# APM32L08x register map
File version: 1.0
CPU: CM0+ r0p0, little endian, MPU, no FPU, 4 interrupt priority bits
Registers are 32-bit, read-write, reset 0x0 unless marked. A register's access mark holds for its fields unless they carry their own. Offsets are from the block's base; [hi:lo] are bit positions; {n}, {i} and the like mark numbered series.

## ADC — Analog-to-digital converter
Base 0x40012400
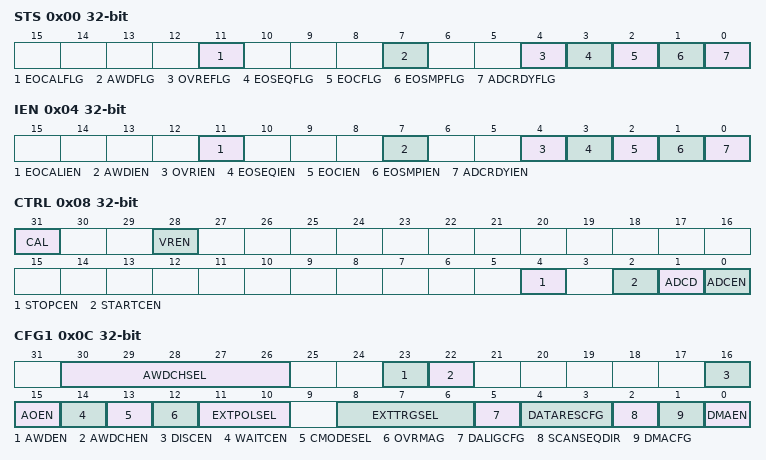
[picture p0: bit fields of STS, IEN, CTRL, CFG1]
0x00 STS — interrupt and status register
  [11] EOCALFLG — End Of Calibration flag
  [7] AWDFLG — Analog watchdog flag
  [4] OVREFLG — ADC overrun
  [3] EOSEQFLG — End of sequence flag
  [2] EOCFLG — End of conversion flag
  [1] EOSMPFLG — End of sampling flag
  [0] ADCRDYFLG — ADC ready
0x04 IEN — interrupt enable register
  [11] EOCALIEN — End of calibration interrupt enable
  [7] AWDIEN — Analog watchdog interrupt enable
  [4] OVRIEN — Overrun interrupt enable
  [3] EOSEQIEN — End of conversion sequence interrupt enable
  [2] EOCIEN — End of conversion interrupt enable
  [1] EOSMPIEN — End of sampling flag interrupt enable
  [0] ADCRDYIEN — ADC ready interrupt enable
0x08 CTRL — control register
  [31] CAL — ADC calibration
  [28] VREN — ADC Voltage Regulator Enable
  [4] STOPCEN — ADC stop conversion command
  [2] STARTCEN — ADC start conversion command
  [1] ADCD — ADC disable command
  [0] ADCEN — ADC enable command
0x0C CFG1 — configuration register 1
  [30:26] AWDCHSEL — Analog watchdog channel selection
  [23] AWDEN — Analog watchdog enable
  [22] AWDCHEN — Enable the watchdog on a single channel or on all channels
  [16] DISCEN — Discontinuous mode
  [15] AOEN — Auto-off mode
  [14] WAITCEN — Auto-delayed conversion mode
  [13] CMODESEL — Single / continuous conversion mode
  [12] OVRMAG — Overrun management mode
  [11:10] EXTPOLSEL — External trigger enable and polarity selection
  [8:6] EXTTRGSEL — External trigger selection
  [5] DALIGCFG — Data alignment
  [4:3] DATARESCFG — Data resolution
  [2] SCANSEQDIR — Scan sequence direction
  [1] DMACFG — Direct memery access configuration
  [0] DMAEN — Direct memory access enable
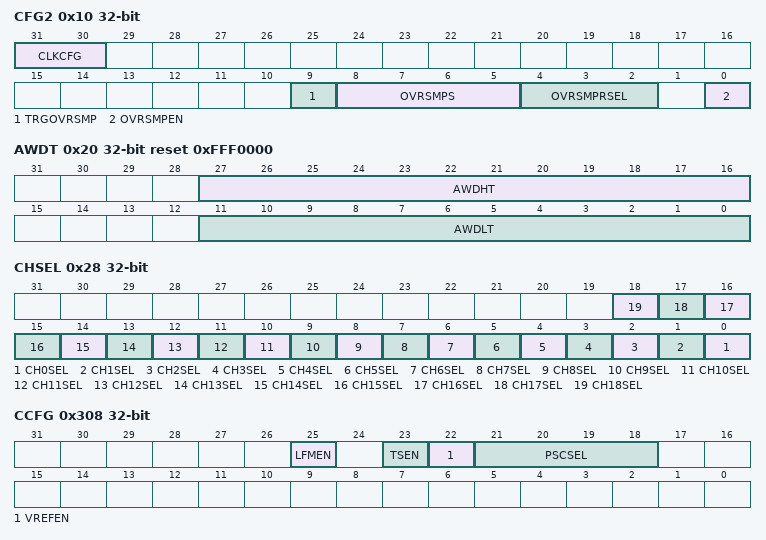
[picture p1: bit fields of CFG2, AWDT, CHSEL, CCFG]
0x10 CFG2 — configuration register 2
  [31:30] CLKCFG — ADC Clock Mode Configure
  [9] TRGOVRSMP — Triggered Oversampling
  [8:5] OVRSMPS — Oversampling shift
  [4:2] OVRSMPRSEL — Oversampling Ratio Select
  [0] OVRSMPEN — Oversampler Enable
0x14 SMPTIM — sampling time register
  [2:0] SMPCYCSEL — Sampling Cycles Selecte
0x20 AWDT reset 0xFFF0000 — watchdog threshold register
  [27:16] AWDHT — Analog watchdog higher threshold
  [11:0] AWDLT — Analog watchdog lower threshold
0x28 CHSEL — channel selection register
  [n] CH{n}SEL (n=0..18) — Channel-x selection
0x40 DATA ro
  [15:0] CDATA — Converted data
0xB4 CALFAC — ADC Calibration factor
  [6:0] CALFAC — Calibration factor
0x308 CCFG — ADC common configuration register
  [25] LFMEN — Low Frequency Mode enable
  [23] TSEN — Temperature sensor enable
  [22] VREFEN — VREFINT enable
  [21:18] PSCSEL — ADC prescaler

## COMP — Comparator
Base 0x40010018
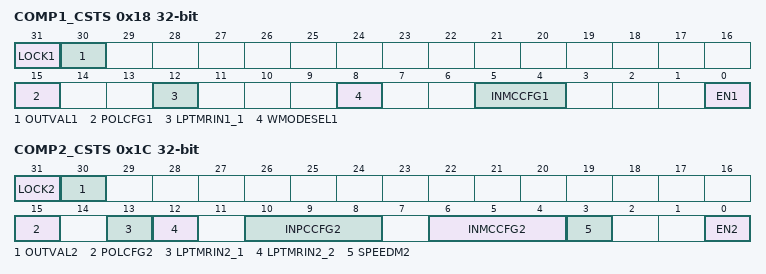
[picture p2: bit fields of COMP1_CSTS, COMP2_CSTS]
0x18 COMP1_CSTS access per field — Comparator 1 control and status register
  [31] LOCK1 wo — COMP1_CSR register lock bit
  [30] OUTVAL1 ro — Comparator 1 output status bit
  [15] POLCFG1 rw — Comparator 1 polarity selection bit
  [12] LPTMRIN1_1 rw — COMP1 output select
  [8] WMODESEL1 rw — Comparator 1 window mode selection bit
  [5:4] INMCCFG1 rw — Comparator 1 Input Minus connection configuration bit
  [0] EN1 rw — Comparator 1 enable bit
0x1C COMP2_CSTS access per field — Comparator 2 control and status register
  [31] LOCK2 wo — COMP2_CSTS Register Lock
  [30] OUTVAL2 ro — Comparator 2 Output Status
  [15] POLCFG2 rw — Comparator 2 Polarity Configure
  [13] LPTMRIN2_1 rw — Comparator 2 LPTMR Input Configure
  [12] LPTMRIN2_2 rw — Comparator 2 LPTMR Input Configure
  [10:8] INPCCFG2 rw — Comparator 2 Input Plus Connection Configure
  [6:4] INMCCFG2 rw — Comparator 2 Input Minus Connection Configure
  [3] SPEEDM2 rw — Comparator 2 Speed Mode Select
  [0] EN2 rw — Comparator 2 enable bit
